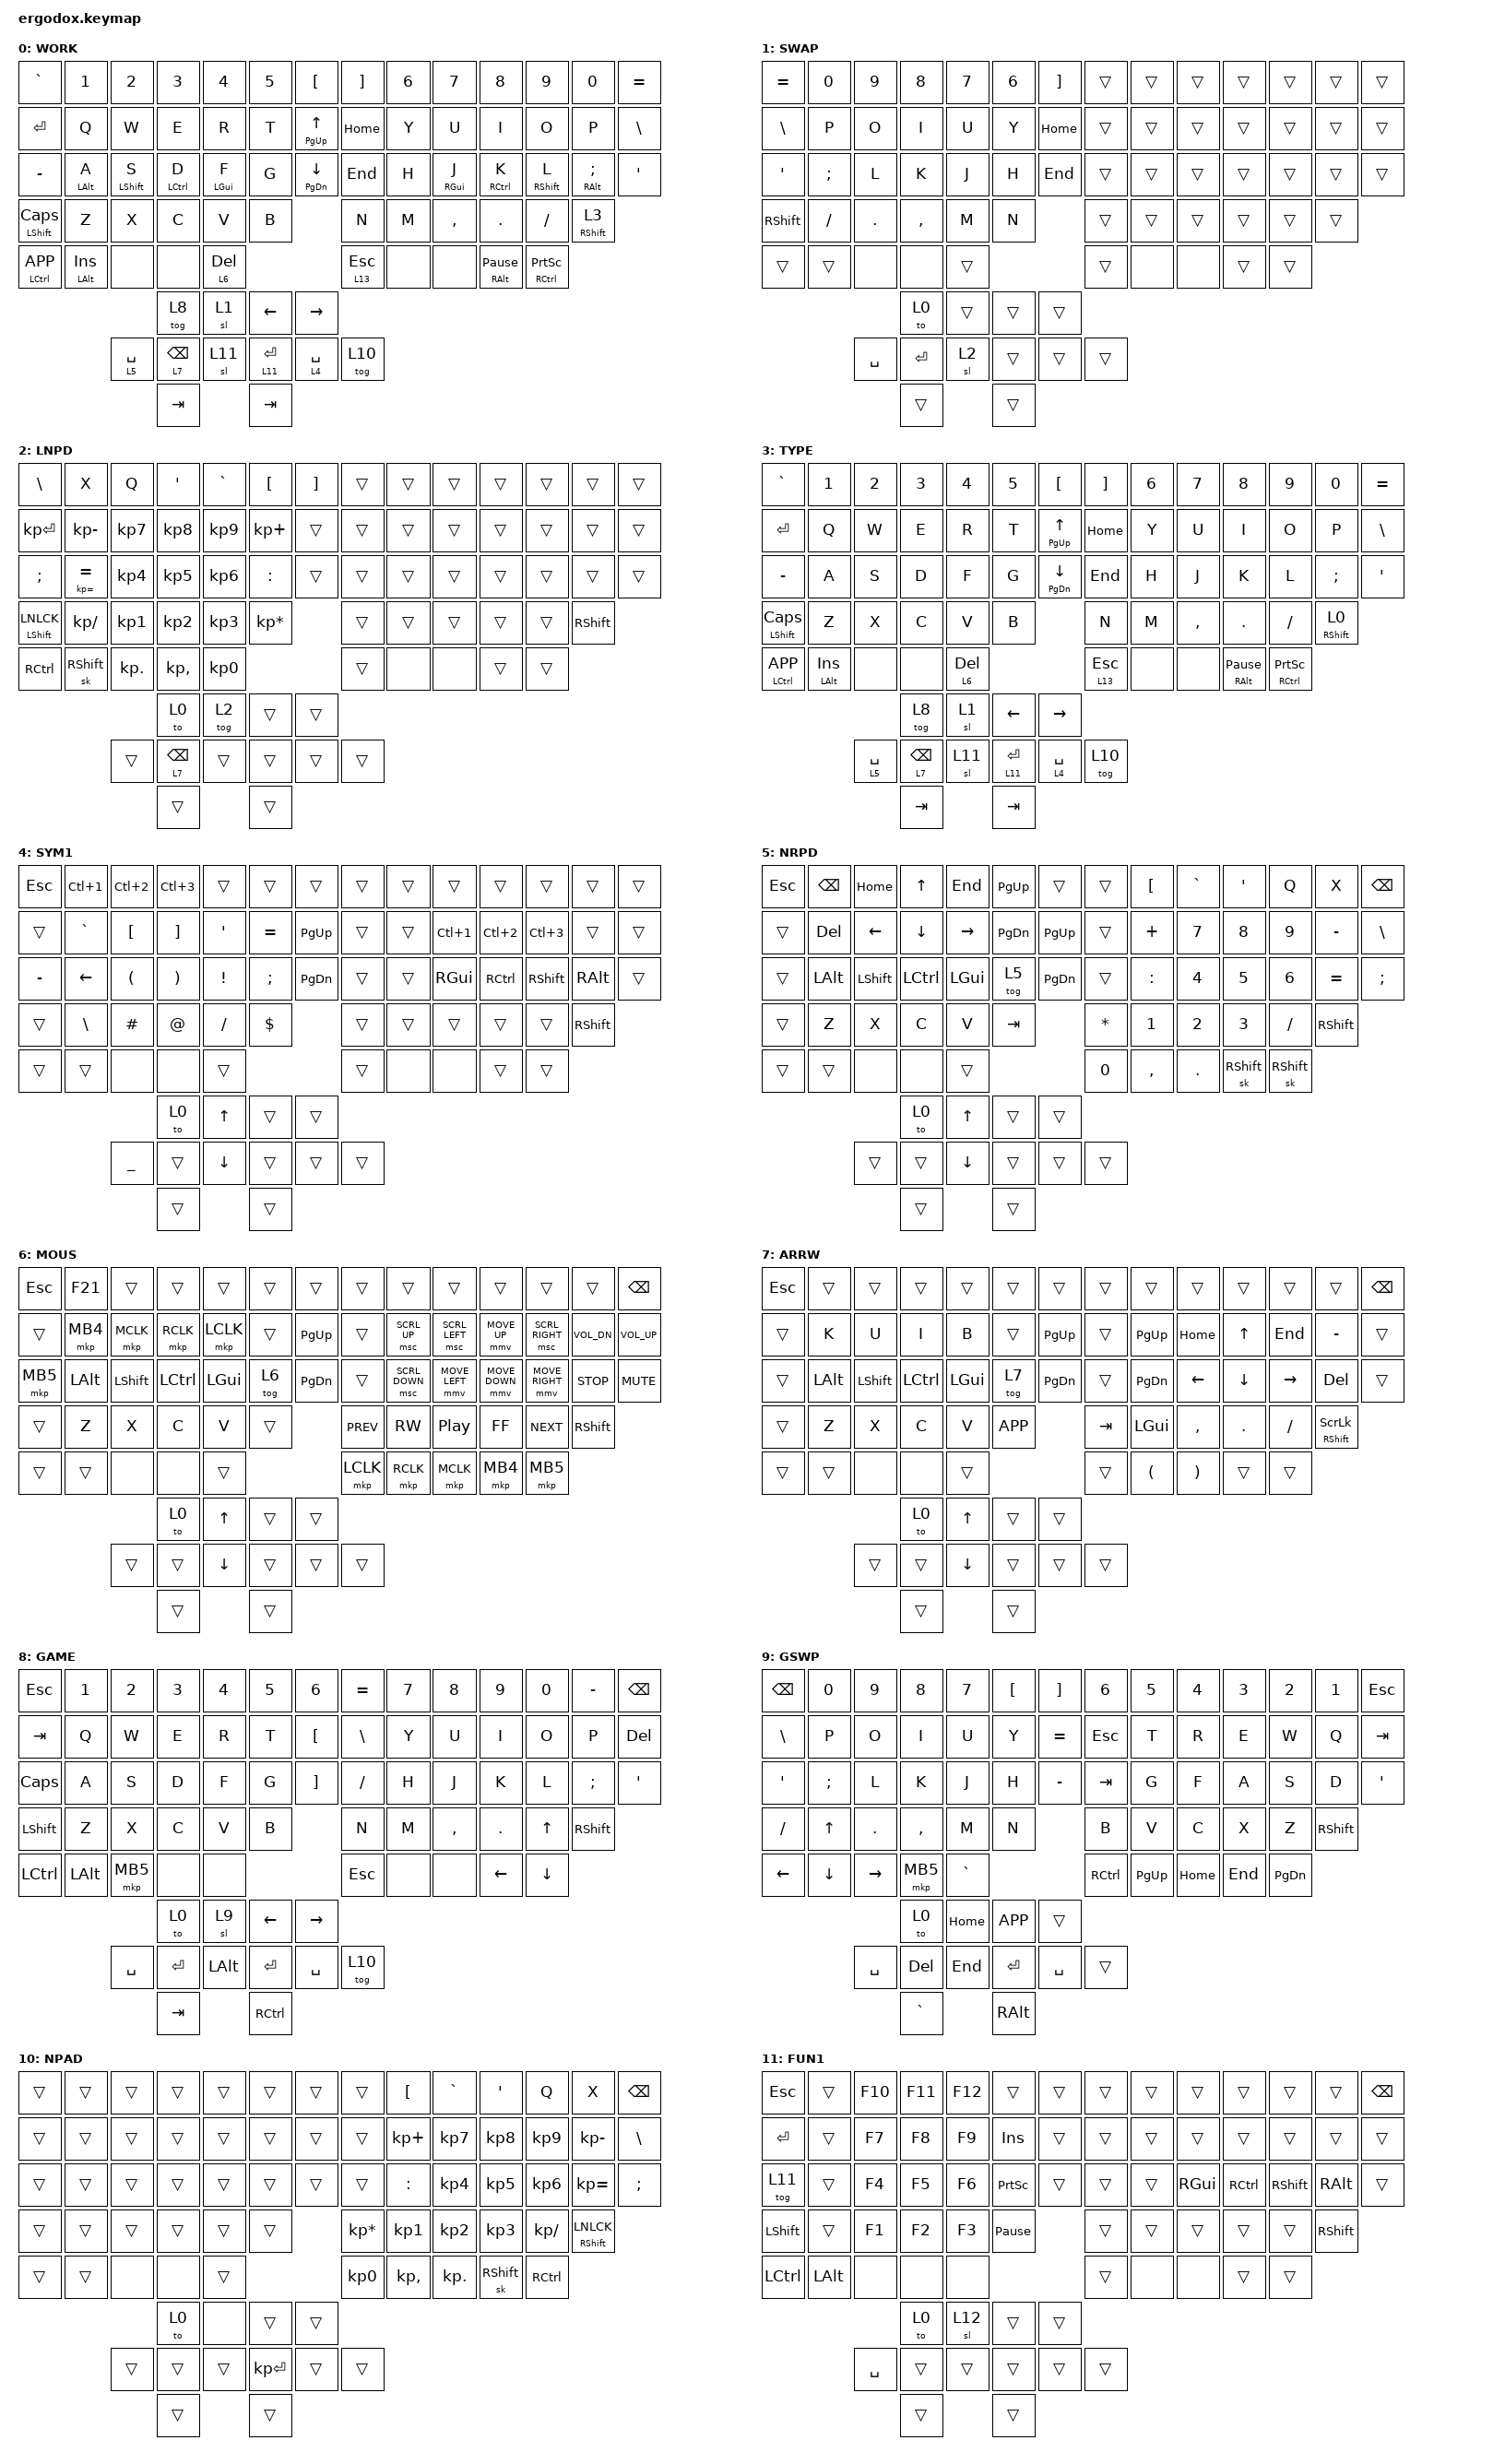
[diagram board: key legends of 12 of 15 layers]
/*
 * Copyright (c) 2026 Starlex & Trevor
 *
 * WORK-TYPE-GAME Layout for ErgoDox Wireless (100% Wireless, Dongle + 2 Peripherals)
 * ZMK Firmware configuration matching interactive layout-viewer 1:1.
 *
 * Generated with Positional Hold-Taps, Dynamic Macros (PR #2678), Mouse Keys,
 * Sticky Layers, ZMK Studio Support (16 layers), and Wireless Dongle management.
 */

#include <behaviors.dtsi>
#include <dt-bindings/zmk/keys.h>
#include <dt-bindings/zmk/bt.h>
#include <dt-bindings/zmk/outputs.h>
#include <dt-bindings/zmk/mouse.h>

// Layer definitions
#define WORK 0
#define SWAP 1
#define LNPD 2
#define TYPE 3
#define SYM1 4
#define NRPD 5
#define MOUS 6
#define ARRW 7
#define GAME 8
#define GSWP 9
#define NPAD 10
#define FUN1 11
#define FUN2 12
#define SYM2 13

/ {
    behaviors {
        // Left hand Home Row Mods: Positional balanced hold-tap
        // Triggers hold ONLY when pressed with keys on the right hand!
        hml: homerow_mods_left {
            compatible = "zmk,behavior-hold-tap";
            #binding-cells = <2>;
            flavor = "balanced";
            tapping-term-ms = <190>;
            quick-tap-ms = <175>;
            require-prior-idle-ms = <150>;
            bindings = <&kp>, <&kp>;
            hold-trigger-key-positions = <7 8 9 10 11 12 13 21 22 23 24 25 26 27 35 36 37 38 39 40 41 48 49 50 51 52 53 59 60 61 62 63 66 67 71 72 73 75>;
            hold-trigger-on-release;
        };

        // Left hand GUI (Win) key: Faster 150ms tapping term
        hml_gui: homerow_mods_left_gui {
            compatible = "zmk,behavior-hold-tap";
            #binding-cells = <2>;
            flavor = "balanced";
            tapping-term-ms = <150>;
            quick-tap-ms = <175>;
            require-prior-idle-ms = <150>;
            bindings = <&kp>, <&kp>;
            hold-trigger-key-positions = <7 8 9 10 11 12 13 21 22 23 24 25 26 27 35 36 37 38 39 40 41 48 49 50 51 52 53 59 60 61 62 63 66 67 71 72 73 75>;
            hold-trigger-on-release;
        };

        // Right hand Home Row Mods: Positional balanced hold-tap
        // Triggers hold ONLY when pressed with keys on the left hand!
        hmr: homerow_mods_right {
            compatible = "zmk,behavior-hold-tap";
            #binding-cells = <2>;
            flavor = "balanced";
            tapping-term-ms = <190>;
            quick-tap-ms = <175>;
            require-prior-idle-ms = <150>;
            bindings = <&kp>, <&kp>;
            hold-trigger-key-positions = <0 1 2 3 4 5 6 14 15 16 17 18 19 20 28 29 30 31 32 33 34 42 43 44 45 46 47 54 55 56 57 58 64 65 68 69 70 74>;
            hold-trigger-on-release;
        };

        // Right hand GUI (Win) key: Faster 150ms tapping term
        hmr_gui: homerow_mods_right_gui {
            compatible = "zmk,behavior-hold-tap";
            #binding-cells = <2>;
            flavor = "balanced";
            tapping-term-ms = <150>;
            quick-tap-ms = <175>;
            require-prior-idle-ms = <150>;
            bindings = <&kp>, <&kp>;
            hold-trigger-key-positions = <0 1 2 3 4 5 6 14 15 16 17 18 19 20 28 29 30 31 32 33 34 42 43 44 45 46 47 54 55 56 57 58 64 65 68 69 70 74>;
            hold-trigger-on-release;
        };

        // Dual-role Right Shift: Hold = Right Shift (&kp), Tap = Layer Switch (&to)
        type_shift: type_shift {
            compatible = "zmk,behavior-hold-tap";
            #binding-cells = <2>;
            flavor = "tap-preferred";
            tapping-term-ms = <200>;
            quick-tap-ms = <175>;
            bindings = <&kp>, <&to>;
        };
    };

    keymap {
        compatible = "zmk,keymap";

        // ---------------------------------------------------------------------------------------------------------------------------------
        // Layer 0: WORK
        // ---------------------------------------------------------------------------------------------------------------------------------
        layer_0 {
            display-name = "WORK";
            bindings = <
            &kp GRAVE       &kp N1          &kp N2          &kp N3          &kp N4          &kp N5          &kp LBKT          &kp RBKT        &kp N6          &kp N7          &kp N8          &kp N9          &kp N0          &kp EQUAL       
            &kp RET         &kp Q           &kp W           &kp E           &kp R           &kp T           &mt PG_UP UP      &kp HOME        &kp Y           &kp U           &kp I           &kp O           &kp P           &kp BSLH        
            &kp MINUS       &hml LALT A     &hml LSHFT S    &hml LCTRL D    &hml_gui LGUI F &kp G           &mt PG_DN DOWN    &kp END         &kp H           &hmr_gui RGUI J &hmr RCTRL K    &hmr RSHFT L    &hmr RALT SEMI  &kp SQT         
            &mt LSHFT CLCK  &kp Z           &kp X           &kp C           &kp V           &kp B                             &kp N           &kp M           &kp COMMA       &kp DOT         &kp FSLH        &type_shift RSHFT 3
            &mt LCTRL K_APP &mt LALT INS    &none           &none           &lt 6 DEL                                         &lt 13 ESC      &none           &none           &mt RALT PAUSE_BREAK&mt RCTRL PSCRN 
                                                          &tog 8          &sl 1             &kp LEFT        &kp RIGHT       
                                                &lt 5 SPACE     &lt 7 BSPC      &sl 11            &lt 11 RET      &lt 4 SPACE     &tog 10         
                                                                    &kp TAB           &kp TAB         
            >;
        };

        // ---------------------------------------------------------------------------------------------------------------------------------
        // Layer 1: SWAP
        // ---------------------------------------------------------------------------------------------------------------------------------
        layer_1 {
            display-name = "SWAP";
            bindings = <
            &kp EQUAL       &kp N0          &kp N9          &kp N8          &kp N7          &kp N6          &kp RBKT          &trans          &trans          &trans          &trans          &trans          &trans          &trans          
            &kp BSLH        &kp P           &kp O           &kp I           &kp U           &kp Y           &kp HOME          &trans          &trans          &trans          &trans          &trans          &trans          &trans          
            &kp SQT         &kp SEMI        &kp L           &kp K           &kp J           &kp H           &kp END           &trans          &trans          &trans          &trans          &trans          &trans          &trans          
            &kp RSHFT       &kp FSLH        &kp DOT         &kp COMMA       &kp M           &kp N                             &trans          &trans          &trans          &trans          &trans          &trans          
            &trans          &trans          &none           &none           &trans                                            &trans          &none           &none           &trans          &trans          
                                                          &to 0           &trans            &trans          &trans          
                                                &kp SPACE       &kp RET         &sl 2             &trans          &trans          &trans          
                                                                    &trans            &trans          
            >;
        };

        // ---------------------------------------------------------------------------------------------------------------------------------
        // Layer 2: LNPD
        // ---------------------------------------------------------------------------------------------------------------------------------
        layer_2 {
            display-name = "LNPD";
            bindings = <
            &kp BSLH        &kp X           &kp Q           &kp SQT         &kp GRAVE       &kp LBKT        &kp RBKT          &trans          &trans          &trans          &trans          &trans          &trans          &trans          
            &kp KP_ENTER    &kp KP_MINUS    &kp KP_N7       &kp KP_N8       &kp KP_N9       &kp KP_PLUS     &trans            &trans          &trans          &trans          &trans          &trans          &trans          &trans          
            &kp SEMI        &mt KP_EQUAL EQUAL&kp KP_N4       &kp KP_N5       &kp KP_N6       &kp COLON       &trans            &trans          &trans          &trans          &trans          &trans          &trans          &trans          
            &mt LSHFT LNLCK &kp KP_DIVIDE   &kp KP_N1       &kp KP_N2       &kp KP_N3       &kp KP_MULTIPLY                   &trans          &trans          &trans          &trans          &trans          &kp RSHFT       
            &kp RCTRL       &sk RSHFT       &kp KP_DOT      &kp KP_COMMA    &kp KP_N0                                         &trans          &none           &none           &trans          &trans          
                                                          &to 0           &tog 2            &trans          &trans          
                                                &trans          &lt 7 BSPC      &trans            &trans          &trans          &trans          
                                                                    &trans            &trans          
            >;
        };

        // ---------------------------------------------------------------------------------------------------------------------------------
        // Layer 3: TYPE
        // ---------------------------------------------------------------------------------------------------------------------------------
        layer_3 {
            display-name = "TYPE";
            bindings = <
            &kp GRAVE       &kp N1          &kp N2          &kp N3          &kp N4          &kp N5          &kp LBKT          &kp RBKT        &kp N6          &kp N7          &kp N8          &kp N9          &kp N0          &kp EQUAL       
            &kp RET         &kp Q           &kp W           &kp E           &kp R           &kp T           &mt PG_UP UP      &kp HOME        &kp Y           &kp U           &kp I           &kp O           &kp P           &kp BSLH        
            &kp MINUS       &kp A           &kp S           &kp D           &kp F           &kp G           &mt PG_DN DOWN    &kp END         &kp H           &kp J           &kp K           &kp L           &kp SEMI        &kp SQT         
            &mt LSHFT CLCK  &kp Z           &kp X           &kp C           &kp V           &kp B                             &kp N           &kp M           &kp COMMA       &kp DOT         &kp FSLH        &type_shift RSHFT 0
            &mt LCTRL K_APP &mt LALT INS    &none           &none           &lt 6 DEL                                         &lt 13 ESC      &none           &none           &mt RALT PAUSE_BREAK&mt RCTRL PSCRN 
                                                          &tog 8          &sl 1             &kp LEFT        &kp RIGHT       
                                                &lt 5 SPACE     &lt 7 BSPC      &sl 11            &lt 11 RET      &lt 4 SPACE     &tog 10         
                                                                    &kp TAB           &kp TAB         
            >;
        };

        // ---------------------------------------------------------------------------------------------------------------------------------
        // Layer 4: SYM1
        // ---------------------------------------------------------------------------------------------------------------------------------
        layer_4 {
            display-name = "SYM1";
            bindings = <
            &kp ESC         &kp LC(N1)      &kp LC(N2)      &kp LC(N3)      &trans          &trans          &trans            &trans          &trans          &trans          &trans          &trans          &trans          &trans          
            &trans          &kp GRAVE       &kp LBKT        &kp RBKT        &kp SQT         &kp EQUAL       &kp PG_UP         &trans          &trans          &kp LC(N1)      &kp LC(N2)      &kp LC(N3)      &trans          &trans          
            &kp MINUS       &kp LEFT        &kp LPAR        &kp RPAR        &kp EXCL        &kp SEMI        &kp PG_DN         &trans          &trans          &kp RGUI        &kp RCTRL       &kp RSHFT       &kp RALT        &trans          
            &trans          &kp BSLH        &kp HASH        &kp AT          &kp FSLH        &kp DLLR                          &trans          &trans          &trans          &trans          &trans          &kp RSHFT       
            &trans          &trans          &none           &none           &trans                                            &trans          &none           &none           &trans          &trans          
                                                          &to 0           &kp UP            &trans          &trans          
                                                &kp UNDER       &trans          &kp DOWN          &trans          &trans          &trans          
                                                                    &trans            &trans          
            >;
        };

        // ---------------------------------------------------------------------------------------------------------------------------------
        // Layer 5: NRPD
        // ---------------------------------------------------------------------------------------------------------------------------------
        layer_5 {
            display-name = "NRPD";
            bindings = <
            &kp ESC         &kp BSPC        &kp HOME        &kp UP          &kp END         &kp PG_UP       &trans            &trans          &kp LBKT        &kp GRAVE       &kp SQT         &kp Q           &kp X           &kp BSPC        
            &trans          &kp DEL         &kp LEFT        &kp DOWN        &kp RIGHT       &kp PG_DN       &kp PG_UP         &trans          &kp PLUS        &kp N7          &kp N8          &kp N9          &kp MINUS       &kp BSLH        
            &trans          &kp LALT        &kp LSHFT       &kp LCTRL       &kp LGUI        &tog 5          &kp PG_DN         &trans          &kp COLON       &kp N4          &kp N5          &kp N6          &kp EQUAL       &kp SEMI        
            &trans          &kp Z           &kp X           &kp C           &kp V           &kp TAB                           &kp ASTRK       &kp N1          &kp N2          &kp N3          &kp FSLH        &kp RSHFT       
            &trans          &trans          &none           &none           &trans                                            &kp N0          &kp COMMA       &kp DOT         &sk RSHFT       &sk RSHFT       
                                                          &to 0           &kp UP            &trans          &trans          
                                                &trans          &trans          &kp DOWN          &trans          &trans          &trans          
                                                                    &trans            &trans          
            >;
        };

        // ---------------------------------------------------------------------------------------------------------------------------------
        // Layer 6: MOUS
        // ---------------------------------------------------------------------------------------------------------------------------------
        layer_6 {
            display-name = "MOUS";
            bindings = <
            &kp ESC         &kp F21         &trans          &trans          &trans          &trans          &trans            &trans          &trans          &trans          &trans          &trans          &trans          &kp BSPC        
            &trans          &mkp MB4        &mkp MCLK       &mkp RCLK       &mkp LCLK       &trans          &kp PG_UP         &trans          &msc SCRL_UP    &msc SCRL_LEFT  &mmv MOVE_UP    &msc SCRL_RIGHT &kp C_VOL_DN    &kp C_VOL_UP    
            &mkp MB5        &kp LALT        &kp LSHFT       &kp LCTRL       &kp LGUI        &tog 6          &kp PG_DN         &trans          &msc SCRL_DOWN  &mmv MOVE_LEFT  &mmv MOVE_DOWN  &mmv MOVE_RIGHT &kp C_STOP      &kp C_MUTE      
            &trans          &kp Z           &kp X           &kp C           &kp V           &trans                            &kp C_PREV      &kp C_RW        &kp C_PP        &kp C_FF        &kp C_NEXT      &kp RSHFT       
            &trans          &trans          &none           &none           &trans                                            &mkp LCLK       &mkp RCLK       &mkp MCLK       &mkp MB4        &mkp MB5        
                                                          &to 0           &kp UP            &trans          &trans          
                                                &trans          &trans          &kp DOWN          &trans          &trans          &trans          
                                                                    &trans            &trans          
            >;
        };

        // ---------------------------------------------------------------------------------------------------------------------------------
        // Layer 7: ARRW
        // ---------------------------------------------------------------------------------------------------------------------------------
        layer_7 {
            display-name = "ARRW";
            bindings = <
            &kp ESC         &trans          &trans          &trans          &trans          &trans          &trans            &trans          &trans          &trans          &trans          &trans          &trans          &kp BSPC        
            &trans          &kp K           &kp U           &kp I           &kp B           &trans          &kp PG_UP         &trans          &kp PG_UP       &kp HOME        &kp UP          &kp END         &kp MINUS       &trans          
            &trans          &kp LALT        &kp LSHFT       &kp LCTRL       &kp LGUI        &tog 7          &kp PG_DN         &trans          &kp PG_DN       &kp LEFT        &kp DOWN        &kp RIGHT       &kp DEL         &trans          
            &trans          &kp Z           &kp X           &kp C           &kp V           &kp K_APP                         &kp TAB         &kp LGUI        &kp COMMA       &kp DOT         &kp FSLH        &mt RSHFT SLCK  
            &trans          &trans          &none           &none           &trans                                            &trans          &kp LPAR        &kp RPAR        &trans          &trans          
                                                          &to 0           &kp UP            &trans          &trans          
                                                &trans          &trans          &kp DOWN          &trans          &trans          &trans          
                                                                    &trans            &trans          
            >;
        };

        // ---------------------------------------------------------------------------------------------------------------------------------
        // Layer 8: GAME
        // ---------------------------------------------------------------------------------------------------------------------------------
        layer_8 {
            display-name = "GAME";
            bindings = <
            &kp ESC         &kp N1          &kp N2          &kp N3          &kp N4          &kp N5          &kp N6            &kp EQUAL       &kp N7          &kp N8          &kp N9          &kp N0          &kp MINUS       &kp BSPC        
            &kp TAB         &kp Q           &kp W           &kp E           &kp R           &kp T           &kp LBKT          &kp BSLH        &kp Y           &kp U           &kp I           &kp O           &kp P           &kp DEL         
            &kp CLCK        &kp A           &kp S           &kp D           &kp F           &kp G           &kp RBKT          &kp FSLH        &kp H           &kp J           &kp K           &kp L           &kp SEMI        &kp SQT         
            &kp LSHFT       &kp Z           &kp X           &kp C           &kp V           &kp B                             &kp N           &kp M           &kp COMMA       &kp DOT         &kp UP          &kp RSHFT       
            &kp LCTRL       &kp LALT        &mkp MB5        &none           &none                                             &kp ESC         &none           &none           &kp LEFT        &kp DOWN        
                                                          &to 0           &sl 9             &kp LEFT        &kp RIGHT       
                                                &kp SPACE       &kp RET         &kp LALT          &kp RET         &kp SPACE       &tog 10         
                                                                    &kp TAB           &kp RCTRL       
            >;
        };

        // ---------------------------------------------------------------------------------------------------------------------------------
        // Layer 9: GSWP
        // ---------------------------------------------------------------------------------------------------------------------------------
        layer_9 {
            display-name = "GSWP";
            bindings = <
            &kp BSPC        &kp N0          &kp N9          &kp N8          &kp N7          &kp LBKT        &kp RBKT          &kp N6          &kp N5          &kp N4          &kp N3          &kp N2          &kp N1          &kp ESC         
            &kp BSLH        &kp P           &kp O           &kp I           &kp U           &kp Y           &kp EQUAL         &kp ESC         &kp T           &kp R           &kp E           &kp W           &kp Q           &kp TAB         
            &kp SQT         &kp SEMI        &kp L           &kp K           &kp J           &kp H           &kp MINUS         &kp TAB         &kp G           &kp F           &kp A           &kp S           &kp D           &kp SQT         
            &kp FSLH        &kp UP          &kp DOT         &kp COMMA       &kp M           &kp N                             &kp B           &kp V           &kp C           &kp X           &kp Z           &kp RSHFT       
            &kp LEFT        &kp DOWN        &kp RIGHT       &mkp MB5        &kp GRAVE                                         &kp RCTRL       &kp PG_UP       &kp HOME        &kp END         &kp PG_DN       
                                                          &to 0           &kp HOME          &kp K_APP       &trans          
                                                &kp SPACE       &kp DEL         &kp END           &kp RET         &kp SPACE       &trans          
                                                                    &kp GRAVE         &kp RALT        
            >;
        };

        // ---------------------------------------------------------------------------------------------------------------------------------
        // Layer 10: NPAD
        // ---------------------------------------------------------------------------------------------------------------------------------
        layer_10 {
            display-name = "NPAD";
            bindings = <
            &trans          &trans          &trans          &trans          &trans          &trans          &trans            &trans          &kp LBKT        &kp GRAVE       &kp SQT         &kp Q           &kp X           &kp BSPC        
            &trans          &trans          &trans          &trans          &trans          &trans          &trans            &trans          &kp KP_PLUS     &kp KP_N7       &kp KP_N8       &kp KP_N9       &kp KP_MINUS    &kp BSLH        
            &trans          &trans          &trans          &trans          &trans          &trans          &trans            &trans          &kp COLON       &kp KP_N4       &kp KP_N5       &kp KP_N6       &kp KP_EQUAL    &kp SEMI        
            &trans          &trans          &trans          &trans          &trans          &trans                            &kp KP_MULTIPLY &kp KP_N1       &kp KP_N2       &kp KP_N3       &kp KP_DIVIDE   &mt RSHFT LNLCK 
            &trans          &trans          &none           &none           &trans                                            &kp KP_N0       &kp KP_COMMA    &kp KP_DOT      &sk RSHFT       &kp RCTRL       
                                                          &to 0           &none             &trans          &trans          
                                                &trans          &trans          &trans            &kp KP_ENTER    &trans          &trans          
                                                                    &trans            &trans          
            >;
        };

        // ---------------------------------------------------------------------------------------------------------------------------------
        // Layer 11: FUN1
        // ---------------------------------------------------------------------------------------------------------------------------------
        layer_11 {
            display-name = "FUN1";
            bindings = <
            &kp ESC         &trans          &kp F10         &kp F11         &kp F12         &trans          &trans            &trans          &trans          &trans          &trans          &trans          &trans          &kp BSPC        
            &kp RET         &trans          &kp F7          &kp F8          &kp F9          &kp INS         &trans            &trans          &trans          &trans          &trans          &trans          &trans          &trans          
            &tog 11         &trans          &kp F4          &kp F5          &kp F6          &kp PSCRN       &trans            &trans          &trans          &kp RGUI        &kp RCTRL       &kp RSHFT       &kp RALT        &trans          
            &kp LSHFT       &trans          &kp F1          &kp F2          &kp F3          &kp PAUSE_BREAK                   &trans          &trans          &trans          &trans          &trans          &kp RSHFT       
            &kp LCTRL       &kp LALT        &none           &none           &none                                             &trans          &none           &none           &trans          &trans          
                                                          &to 0           &sl 12            &trans          &trans          
                                                &kp SPACE       &trans          &trans            &trans          &trans          &trans          
                                                                    &trans            &trans          
            >;
        };

        // ---------------------------------------------------------------------------------------------------------------------------------
        // Layer 12: FUN2
        // ---------------------------------------------------------------------------------------------------------------------------------
        layer_12 {
            display-name = "FUN2";
            bindings = <
            &kp ESC         &trans          &kp F22         &kp F23         &kp F24         &trans          &trans            &trans          &trans          &trans          &trans          &trans          &trans          &kp BSPC        
            &kp RET         &trans          &kp F19         &kp F20         &kp F21         &kp INS         &trans            &trans          &trans          &trans          &trans          &trans          &trans          &trans          
            &tog 12         &trans          &kp F16         &kp F17         &kp F18         &kp PSCRN       &trans            &trans          &trans          &kp RGUI        &kp RCTRL       &kp RSHFT       &kp RALT        &trans          
            &kp LSHFT       &trans          &kp F13         &kp F14         &kp F15         &kp PAUSE_BREAK                   &trans          &trans          &trans          &trans          &trans          &kp RSHFT       
            &kp LCTRL       &kp LALT        &none           &none           &none                                             &trans          &none           &none           &trans          &trans          
                                                          &to 0           &none             &trans          &trans          
                                                &kp SPACE       &trans          &trans            &trans          &trans          &trans          
                                                                    &trans            &trans          
            >;
        };

        // ---------------------------------------------------------------------------------------------------------------------------------
        // Layer 13: SYM2
        // ---------------------------------------------------------------------------------------------------------------------------------
        layer_13 {
            display-name = "SYM2";
            bindings = <
            &out OUT_TOG    &bt BT_SEL 0    &bt BT_SEL 1    &bt BT_SEL 2    &bt BT_SEL 3    &bt BT_SEL 4    &bt BT_CLR        &bt BT_CLR      &bt BT_SEL 0    &bt BT_SEL 1    &bt BT_SEL 2    &bt BT_SEL 3    &bt BT_SEL 4    &kp BSPC        
            &trans          &kp TILDE       &kp LBRC        &kp RBRC        &kp DQT         &kp PLUS        &kp PG_UP         &trans          &trans          &trans          &trans          &trans          &trans          &trans          
            &trans          &kp LEFT        &kp LT          &kp GT          &kp AMPS        &kp COLON       &kp PG_DN         &trans          &trans          &kp RGUI        &kp RCTRL       &kp RSHFT       &kp RALT        &trans          
            &trans          &kp QMARK       &kp CARET       &kp PRCNT       &kp PIPE        &kp ASTRK                         &trans          &tog 5          &tog 7          &tog 6          &trans          &kp RSHFT       
            &trans          &trans          &trans          &trans          &trans                                            &trans          &trans          &trans          &trans          &trans          
                                                          &to 0           &kp UP            &trans          &trans          
                                                &trans          &trans          &kp DOWN          &trans          &trans          &none           
                                                                    &trans            &out OUT_TOG    
            >;
        };

        // ---------------------------------------------------------------------------------------------------------------------------------
        // Layer 14: MENU
        // ---------------------------------------------------------------------------------------------------------------------------------
        layer_14 {
            display-name = "MENU";
            bindings = <
            &none           &none           &none           &none           &none           &none           &none             &none           &none           &none           &none           &none           &none           &none           
            &none           &none           &none           &none           &none           &none           &none             &none           &none           &none           &none           &none           &none           &none           
            &none           &none           &none           &none           &none           &none           &none             &none           &none           &none           &none           &none           &none           &none           
            &none           &none           &none           &none           &none           &none                             &none           &none           &none           &none           &none           &none           
            &none           &none           &none           &none           &none                                             &none           &none           &none           &none           &none           
                                                          &none           &none             &none           &none           
                                                &none           &none           &none             &none           &none           &none           
                                                                    &none             &none           
            >;
        };
    };
};
